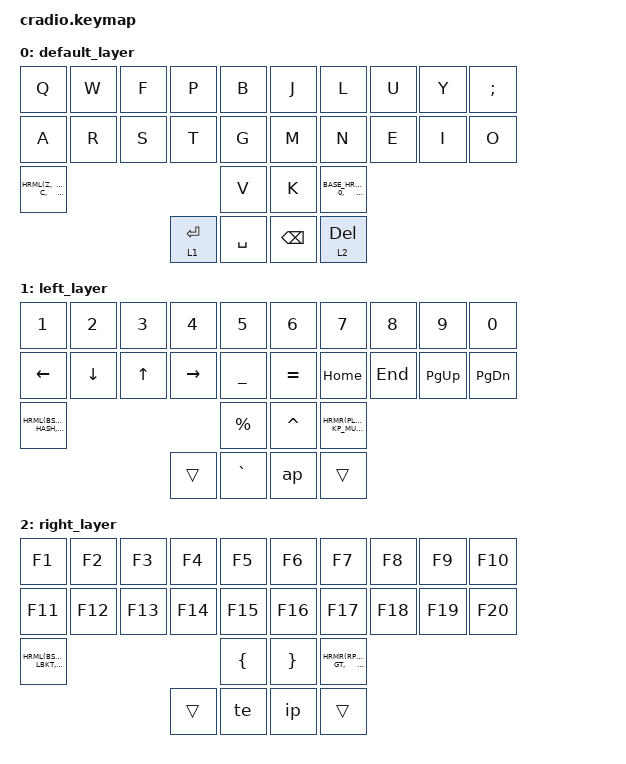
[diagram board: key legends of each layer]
// Copyright (c) 2022 The ZMK Contributors
// SPDX-License-Identifier: MIT

#include <behaviors.dtsi>
#include <dt-bindings/zmk/keys.h>
#include <dt-bindings/zmk/bt.h>
// #include <dt-bindings/zmk/pointing.h>

#define FLAVOR "balanced"
#define TAPPING_TERM_MS 200
#define QUICK_TAP_MS 150
#define REQUIRE_PRIOR_IDLE_MS 100

// Home row mods macro
#define HRML(k1,k2,k3,k4) &ht LGUI k1  &ht LALT k2  &ht LSHFT k3  &ht LCTRL k4
#define HRMR(k1,k2,k3,k4) &ht RCTRL k1  &ht RSHFT k2  &ht RALT k3  &ht RGUI k4

#define BASE_HRMR(k1,k2,k3,k4) &ht RCTRL k1  &cq_ht RSHFT k2  &de_ht RALT k3  &ht RGUI k4

/ {
    behaviors {
        ht: hold_tap {
            compatible = "zmk,behavior-hold-tap";
            #binding-cells = <2>;
            flavor = FLAVOR;
            tapping-term-ms = <TAPPING_TERM_MS>;
            quick-tap-ms = <QUICK_TAP_MS>;
            require-prior-idle-ms = <REQUIRE_PRIOR_IDLE_MS>;
            bindings = <&kp>, <&kp>;
        };

        cq: comma_qmark {
            compatible = "zmk,behavior-mod-morph";
            label = "COMMA_QMARK";
            #binding-cells = <0>;
            bindings = <&kp COMMA>, <&kp QMARK>;
            mods = <(MOD_LSFT | MOD_RSFT)>;
            display-name = "Comma/QuestionMark";
        };

        de: dot_excl {
            compatible = "zmk,behavior-mod-morph";
            label = "DOT_EXCL";
            #binding-cells = <0>;
            bindings = <&kp DOT>, <&kp EXCL>;
            mods = <(MOD_LSFT | MOD_RSFT)>;
            display-name = "Dot/ExlamationMark";
        };

        ap: amps_pipe {
            compatible = "zmk,behavior-mod-morph";
            label = "AMPS_PIPE";
            #binding-cells = <0>;
            bindings = <&kp AMPS>, <&kp PIPE>;
            mods = <(MOD_LSFT | MOD_RSFT)>;
            display-name = "Ampersand/Pipe";
        };
        
        te: tab_esc {
            compatible = "zmk,behavior-mod-morph";
            label = "TAB_ESC";
            #binding-cells = <0>;
            bindings = <&kp TAB>, <&kp ESC>;
            mods = <(MOD_LSFT | MOD_RSFT)>;
            display-name = "Tab/Escape";
        };
        
        ip: ins_pscrn {
            compatible = "zmk,behavior-mod-morph";
            label = "INS_PSCRN";
            #binding-cells = <0>;
            bindings = <&kp INS>, <&kp PSCRN>;
            mods = <(MOD_LSFT | MOD_RSFT)>;
            display-name = "Insert/PrintScreen";
        };

        cq_ht: comma_qmark_hold_tap {
            compatible = "zmk,behavior-hold-tap";
            #binding-cells = <2>;
            flavor = FLAVOR;
            tapping-term-ms = <TAPPING_TERM_MS>;
            quick-tap-ms = <QUICK_TAP_MS>;
            require-prior-idle-ms = <REQUIRE_PRIOR_IDLE_MS>;
            bindings = <&kp>, <&cq>;
        };
        
        de_ht: dot_excl_hold_tap {
            compatible = "zmk,behavior-hold-tap";
            #binding-cells = <2>;
            flavor = FLAVOR;
            tapping-term-ms = <TAPPING_TERM_MS>;
            quick-tap-ms = <QUICK_TAP_MS>;
            require-prior-idle-ms = <REQUIRE_PRIOR_IDLE_MS>;
            bindings = <&kp>, <&de>;
        };
    };

    keymap {
        compatible = "zmk,keymap";
        
        default_layer {
            bindings = <
        //╭─────────────────┬─────────────────┬─────────────────┬─────────────────┬─────────────────╮   ╭─────────────────┬─────────────────┬─────────────────┬─────────────────┬─────────────────╮
        //│  Q              │  W              │  E              │  R              │  T              │   │  Y              │  U              │  I              │  O              │  P              │
            &kp Q            &kp W             &kp F             &kp P             &kp B                 &kp J             &kp L             &kp U             &kp Y             &kp SEMI
        //├─────────────────┼─────────────────┼─────────────────┼─────────────────┼─────────────────┤   ├─────────────────┼─────────────────┼─────────────────┼─────────────────┼─────────────────┤
        //│  A              │  S              │  D              │  F              │  G              │   │  H              │  J              │  K              │  L              │ ' "             │
            &kp A             &kp R             &kp S             &kp T             &kp G                 &kp M             &kp N             &kp E             &kp I             &kp O
        //├─────────────────┼─────────────────┼─────────────────┼─────────────────┼─────────────────┤   ├─────────────────┼─────────────────┼─────────────────┼─────────────────┼─────────────────┤
        //│  Z              │  X              │  C              │  V              │  B              │   │  N              │  M              │  , ?            │  . !            │ ; :             │
            HRML(Z,               X,                C,                D)            &kp V                 &kp K             BASE_HRMR(H,          0,                0,               APOS)
        //╰─────────────────┴─────────────────┴─────────────────┼─────────────────┼─────────────────┤   ├─────────────────┼─────────────────┼─────────────────┴─────────────────┴─────────────────╯
                                                                   &lt 1 ENTER      &kp SPACE             &kp BSPC          &lt 2 DEL
        //                                                      ╰─────────────────┴─────────────────╯   ╰─────────────────┴─────────────────╯
            >;
        };

        left_layer {
            bindings = <
        //╭─────────────────┬─────────────────┬─────────────────┬─────────────────┬─────────────────╮   ╭─────────────────┬─────────────────┬─────────────────┬─────────────────┬─────────────────╮
        //│  1              │  2              │  3              │  4              │  5              │   │  6              │  7              │  8              │  9              │  0              │
            &kp N1            &kp N2            &kp N3            &kp N4            &kp N5                &kp N6            &kp N7            &kp N8            &kp N9            &kp N0
        //├─────────────────┼─────────────────┼─────────────────┼─────────────────┼─────────────────┤   ├─────────────────┼─────────────────┼─────────────────┼─────────────────┼─────────────────┤
        //│ LEFT            │ DOWN            │ UP              │ RIGHT           │  _              │   │  =              │ HOME            │ END             │ PG UP           │ PG DN           │
            &kp LEFT          &kp DOWN          &kp UP            &kp RIGHT         &kp UNDER             &kp EQUAL         &kp HOME          &kp END           &kp PG_UP         &kp PG_DN
        //├─────────────────┼─────────────────┼─────────────────┼─────────────────┼─────────────────┤   ├─────────────────┼─────────────────┼─────────────────┼─────────────────┼─────────────────┤
        //│  \              │  @              │  #              │  $              │  %              │   │  ^              │  +              │  -              │  *              │  /              │
            HRML(BSLH,            AT,               HASH,              DLLR)        &kp PRCNT             &kp CARET         HRMR(PLUS,            KP_MINUS,         KP_MULTIPLY,      KP_DIVIDE)
        //╰─────────────────┴─────────────────┴─────────────────┼─────────────────┼─────────────────┤   ├─────────────────┼─────────────────┼─────────────────┴─────────────────┴─────────────────╯
                                                                  &trans            &kp GRAVE             &ap               &trans
        //                                                      ╰─────────────────┴─────────────────╯   ╰─────────────────┴─────────────────╯
            >;
        };

        right_layer {
            bindings = <
        //╭─────────────────┬─────────────────┬─────────────────┬─────────────────┬─────────────────╮   ╭─────────────────┬─────────────────┬─────────────────┬─────────────────┬─────────────────╮
        //│  F1             │  F2             │  F3             │  F4             │  F5             │   │  F6             │  F7             │  F8             │  F9             │  F10            │
            &kp F1            &kp F2            &kp F3            &kp F4            &kp F5                &kp F6            &kp F7            &kp F8            &kp F9            &kp F10
        //├─────────────────┼─────────────────┼─────────────────┼─────────────────┼─────────────────┤   ├─────────────────┼─────────────────┼─────────────────┼─────────────────┼─────────────────┤
        //│ MOUSE LEFT      │ MOUSE DOWN      │ MOUSE UP        │ MOUSE RIGHT     │  F11            │   │  F12            │ LEFT CLICK      │ RIGHT CLICK     │ SCROLL UP       │ SCROLL DOWN     │
        //    &mmv MOVE_LEFT    &mmv MOVE_DOWN    &mmv MOVE_UP      &mmv MOVE_RIGHT   &kp F11               &kp F12           &mkp MB1          &mkp MB2          &msc SCRL_UP      &msc SCRL_DOWN
              &kp F11           &kp F12           &kp F13           &kp F14           &kp F15               &kp F16           &kp F17           &kp F18           &kp F19           &kp F20
        //├─────────────────┼─────────────────┼─────────────────┼─────────────────┼─────────────────┤   ├─────────────────┼─────────────────┼─────────────────┼─────────────────┼─────────────────┤
        //│  \              │  <              │  [              │  (              │  {              │   │  }              │  )              │  ]              │  >              │  /              │
            HRML(BSLH,           LT,               LBKT,             LPAR)             &kp LBRC           &kp RBRC          HRMR(RPAR,            RBKT,             GT,              KP_DIVIDE)
        //╰─────────────────┴─────────────────┴─────────────────┼─────────────────┼─────────────────┤   ├─────────────────┼─────────────────┼─────────────────┴─────────────────┴─────────────────╯
                                                                  &trans            &te                   &ip               &trans
        //                                                      ╰─────────────────┴─────────────────╯   ╰─────────────────┴─────────────────╯
            >;
        };
    };
};
